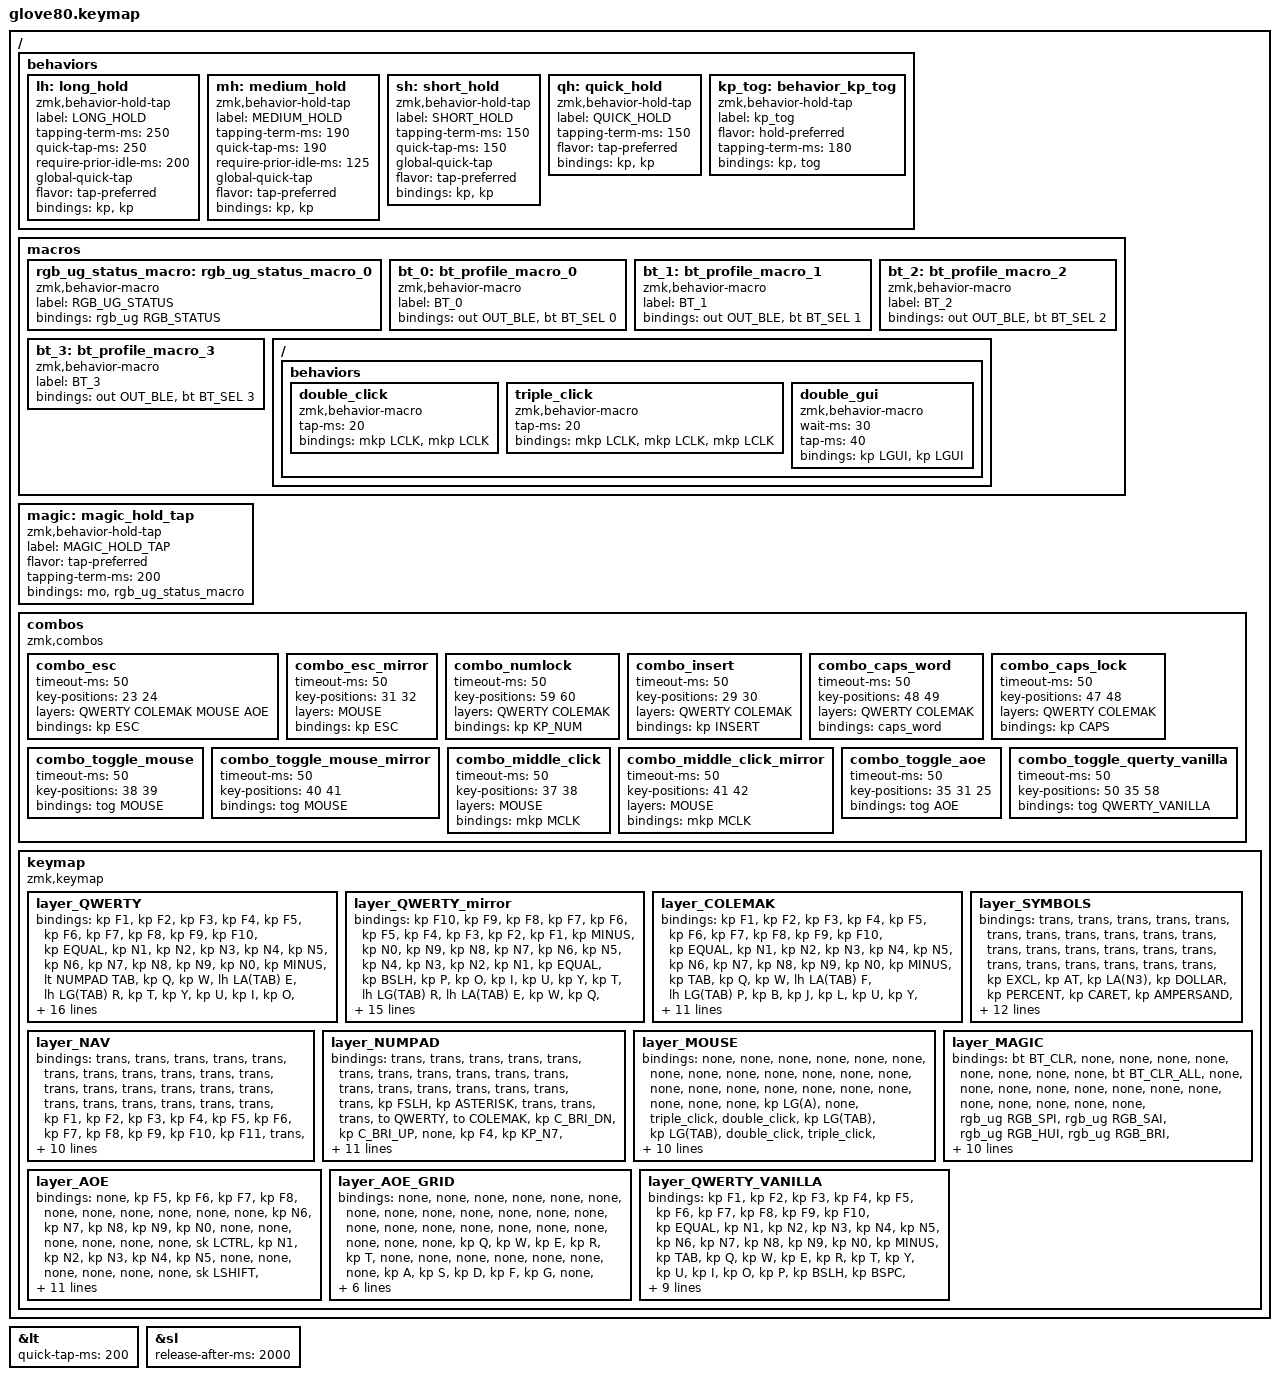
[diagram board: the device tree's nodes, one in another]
/*
 * Copyright (c) 2020 The ZMK Contributors
 * Copyright (c) 2022 Innaworks Development Limited, trading as MoErgo
 *
 * SPDX-License-Identifier: MIT
 */

#include <behaviors.dtsi>
/* Include all behaviour includes needed by system behaviors/macros */
#include <dt-bindings/zmk/outputs.h>

/* Include behaviour includes needed by key binds - automatically generated */
#include <dt-bindings/zmk/keys.h>
#include <dt-bindings/zmk/bt.h>
#include <dt-bindings/zmk/rgb.h>
#include <dt-bindings/zmk/outputs.h>
#include <dt-bindings/zmk/mouse.h>

#define QWERTY 0
#define QWERTY_MIRROR 1
#define COLEMAK 2
#define SYMBOLS 3
#define NAV 4
#define NUMPAD 5
#define MOUSE 6
#define MAGIC 7
#define AOE 8
#define AOE_GRID 9
#define QWERTY_VANILLA 10

#define AS(keycode) &qh LS(keycode) keycode     // Autoshift Macro

&lt {
    quick-tap-ms = <200>;
};

&sl {
    release-after-ms = <2000>;
};

/ {
    behaviors {
        /* Tap and hold with a longer duration for keys that invoke functions (e.g. alt-tabbing, etc.) */
        lh: long_hold {
            compatible = "zmk,behavior-hold-tap";
            label = "LONG_HOLD";
            #binding-cells = <2>;
            tapping-term-ms = <250>;
            quick-tap-ms = <250>;
            require-prior-idle-ms = <200>;
            global-quick-tap;
            flavor = "tap-preferred";
            bindings = <&kp>, <&kp>;
        };

        /* Tap and hold with a medium duration, e.g. for home-row modifiers */
        mh: medium_hold {
            compatible = "zmk,behavior-hold-tap";
            label = "MEDIUM_HOLD";
            #binding-cells = <2>;
            tapping-term-ms = <190>;
            quick-tap-ms = <190>;
            require-prior-idle-ms = <125>;
            global-quick-tap;
            flavor = "tap-preferred";
            bindings = <&kp>, <&kp>;
        };

        /*
           Short holds optimised for faster typing. Use for the shift key home-row mods on character layers.
           Same as medium hold but without require-prior-idle and shorter tapping terms
        */
        sh: short_hold {
            compatible = "zmk,behavior-hold-tap";
            label = "SHORT_HOLD";
            #binding-cells = <2>;
            tapping-term-ms = <150>;
            quick-tap-ms = <150>;
            global-quick-tap;
            flavor = "tap-preferred";
            bindings = <&kp>, <&kp>;
        };

        /* Tap and hold with a short duration for normal keys (i.e. shift left/right keys) */
        qh: quick_hold {
            compatible = "zmk,behavior-hold-tap";
            label = "QUICK_HOLD";
            #binding-cells = <2>;
            tapping-term-ms = <150>;
            flavor = "tap-preferred";
            bindings = <&kp>, <&kp>;
        };

        /* Toggle layer on tap, kp on hold */
        kp_tog: behavior_kp_tog {
            compatible = "zmk,behavior-hold-tap";
            label = "kp_tog";
            #binding-cells = <2>;
            flavor = "hold-preferred";
            tapping-term-ms = <180>;
            bindings = <&kp>, <&tog>;
        };
    };
};

/ {
    macros {
        rgb_ug_status_macro: rgb_ug_status_macro_0 {
            label = "RGB_UG_STATUS";
            compatible = "zmk,behavior-macro";
            #binding-cells = <0>;
            bindings
                = <&rgb_ug RGB_STATUS>;
        };

        bt_0: bt_profile_macro_0 {
            label = "BT_0";
            compatible = "zmk,behavior-macro";
            #binding-cells = <0>;
            bindings
                = <&out OUT_BLE>,
                  <&bt BT_SEL 0>;
        };

        bt_1: bt_profile_macro_1 {
            label = "BT_1";
            compatible = "zmk,behavior-macro";
            #binding-cells = <0>;
            bindings
                = <&out OUT_BLE>,
                  <&bt BT_SEL 1>;
        };

        bt_2: bt_profile_macro_2 {
            label = "BT_2";
            compatible = "zmk,behavior-macro";
            #binding-cells = <0>;
            bindings
                = <&out OUT_BLE>,
                  <&bt BT_SEL 2>;
        };

        bt_3: bt_profile_macro_3 {
            label = "BT_3";
            compatible = "zmk,behavior-macro";
            #binding-cells = <0>;
            bindings
                = <&out OUT_BLE>,
                  <&bt BT_SEL 3>;
        };

        /* Mouse double left-click */
        ZMK_MACRO(double_click,
            tap-ms = <20>;
            bindings = <&mkp LCLK &mkp LCLK>;
        )

        /* Mouse triple left-click */
        ZMK_MACRO(triple_click,
            tap-ms = <20>;
            bindings = <&mkp LCLK &mkp LCLK &mkp LCLK>;
        )

        /* Double press command key (to trigger dictation on mac) */
        ZMK_MACRO(double_gui,
            wait-ms = <30>;
            tap-ms = <40>;
            bindings = <&kp LGUI &kp LGUI>;
        )
    };
};

/ {
    magic: magic_hold_tap {
        compatible = "zmk,behavior-hold-tap";
        label = "MAGIC_HOLD_TAP";
        #binding-cells = <2>;
        flavor = "tap-preferred";
        tapping-term-ms = <200>;
        bindings = <&mo>, <&rgb_ug_status_macro>;
    };
};

    /* Custom Defined Behaviors */
/ {

};

/ {
    combos {
        compatible = "zmk,combos";

        /* ESC when pressing keys in the position of Q & W on the QWERTY keymap simultaneously */
        combo_esc {
            timeout-ms = <50>;
            key-positions = <23 24>;
            layers = <QWERTY COLEMAK MOUSE AOE>;
            bindings = <&kp ESC>;
        };

        /* ESC when pressing keys in the position of O & P on the QWERTY keymap simultaneously */
        combo_esc_mirror {
            timeout-ms = <50>;
            key-positions = <31 32>;
            layers = <MOUSE>;
            bindings = <&kp ESC>;
        };

        /* NUMLOCK when pressing keys in the position of M & comma on the QWERTY keymap simultaneously */
        combo_numlock {
            timeout-ms = <50>;
            key-positions = <59 60>;
            layers = <QWERTY COLEMAK>;
            bindings = <&kp KP_NUM>;
        };

        /* INSERT when pressing keys in the position of U & I on the QWERTY keymap simultaneously */
        combo_insert {
            timeout-ms = <50>;
            key-positions = <29 30>;
            layers = <QWERTY COLEMAK>;
            bindings = <&kp INSERT>;
        };

        /* Caps word when pressing the keys in the position of X & C on the QWERTY keymap simultaneously */
        combo_caps_word {
            timeout-ms = <50>;
            key-positions = <48 49>;
            layers = <QWERTY COLEMAK>;
            bindings = <&caps_word>;
        };

        /* Caps lock when pressing the keys in the position of Z & X on the QWERTY keymap simultaneously */
        combo_caps_lock {
            timeout-ms = <50>;
            key-positions = <47 48>;
            layers = <QWERTY COLEMAK>;
            bindings = <&kp CAPS>;
        };

        /* Toggle the mouse layer when pressing F and G */
        combo_toggle_mouse {
            timeout-ms = <50>;
            key-positions = <38 39>;
            bindings = <&tog MOUSE>;
        };

        /* Toggle the mouse layer when pressing H and J */
        combo_toggle_mouse_mirror {
            timeout-ms = <50>;
            key-positions = <40 41>;
            bindings = <&tog MOUSE>;
        };

        /* Middle mouse click when pressing D & F on the mouse layer */
        combo_middle_click {
            timeout-ms = <50>;
            key-positions = <37 38>;
            layers = <MOUSE>;
            bindings = <&mkp MCLK>;
        };

        /* Middle mouse click when pressing J & K on the mouse layer */
        combo_middle_click_mirror {
            timeout-ms = <50>;
            key-positions = <41 42>;
            layers = <MOUSE>;
            bindings = <&mkp MCLK>;
        };

        /* Toggle the AOE layer when pressing A & O & E */
        combo_toggle_aoe {
            timeout-ms = <50>;
            key-positions = <35 31 25>;
            bindings = <&tog AOE>;
        };

        /* Toggle the QWERTY_VANILLA layer when pressing V & A & N */
        combo_toggle_querty_vanilla {
            timeout-ms = <50>;
            key-positions = <50 35 58>;
            bindings = <&tog QWERTY_VANILLA>;
        };
    };
};

/ {
    keymap {
        compatible = "zmk,keymap";

        layer_QWERTY {
            bindings = <
        &kp F1               &kp F2         &kp F3        &kp F4          &kp F5                                                                                                                                                                                       &kp F6       &kp F7       &kp F8        &kp F9            &kp F10
        &kp EQUAL            &kp N1         &kp N2        &kp N3          &kp N4          &kp N5                                                                                                                                                          &kp N6       &kp N7       &kp N8       &kp N9        &kp N0            &kp MINUS
        &lt NUMPAD TAB       &kp Q          &kp W         &lh LA(TAB) E   &lh LG(TAB) R   &kp T                                                                                                                                                           &kp Y        &kp U        &kp I        &kp O         &kp P             &lt NUMPAD BSLH
        &lt SYMBOLS BSPC     &sh LSHIFT A   &mh LCTRL S   &mh LALT D      &mh LGUI F      &mh LGUI G                                                                                                                                                      &mh RGUI H   &mh RGUI J   &mh LALT K   &mh RCTRL L   &sh RSHIFT SEMI   &lt SYMBOLS RET
        &lt NAV GRAVE        &lh LG(Z) Z    &lh LG(X) X   &mh LG(C) C     &lh LG(V) V     &kp B        &kp_tog LSHFT NAV   &kp_tog LCTRL NUMPAD   &kp_tog LGUI QWERTY_MIRROR        &kp_tog LGUI QWERTY_MIRROR   &kp RCTRL  &kp_tog RSHFT SYMBOLS         &kp N        &kp M        &kp COMMA    &kp DOT       &kp FSLH          &lt NAV PG_UP
        &magic MAGIC QWERTY  &kp HOME       &kp END       &kp LEFT        &kp RIGHT                    &lt NAV BSPC        &lt NUMPAD TAB         &kp LALT                          &kp     RALT                 &kp RET    &lt SYMBOLS SPACE                          &kp UP       &kp DOWN     &kp LBKT      &kp RBKT          &kp PG_DN
            >;
        };

        /* The above layout mirrored */
        layer_QWERTY_mirror {
            bindings = <
        &kp F10     &kp F9            &kp F8        &kp F7        &kp F6                                                                                                                                                                                  &kp F5          &kp F4          &kp F3        &kp F2            &kp F1
        &kp MINUS   &kp N0            &kp N9        &kp N8        &kp N7          &kp N6                                                                                                                                                     &kp N5       &kp N4          &kp N3          &kp N2        &kp N1            &kp EQUAL
        &kp BSLH    &kp P             &kp O         &kp I         &kp U           &kp Y                                                                                                                                                      &kp T        &lh LG(TAB) R   &lh LA(TAB) E   &kp W         &kp Q             &kp TAB
        &kp SQT     &sh RSHIFT SEMI   &mh RCTRL L   &mh LALT K    &mh RGUI J      &mh RGUI H                                                                                                                                                 &mh LGUI G   &mh LGUI F      &mh LALT D      &mh LCTRL S   &sh LSHIFT A      &kp ESC
        &kp PG_UP   &kp FSLH          &kp DOT       &kp COMMA     &kp M           &kp N       &kp_tog RSHFT SYMBOLS   &kp RCTRL   &kp_tog LGUI QWERTY_MIRROR        &kp_tog LGUI QWERTY_MIRROR   &kp_tog LCTRL NUMPAD   &kp_tog LSHFT NAV    &kp B        &lh LG(V) V     &mh LG(C) C     &lh LG(X) X   &lh LG(Z) Z       &kp GRAVE
        &kp PG_DN   &kp RBKT          &kp LBKT      &kp DOWN      &kp UP                      &lt SYMBOLS SPACE       &kp RET     &kp LALT                          &kp     RALT                 &lt NUMPAD TAB         &lt NAV BSPC                      &kp RIGHT       &kp LEFT        &kp END       &kp HOME          &magic MAGIC QWERTY
            >;
        };

        layer_COLEMAK {
            bindings = <
       &kp F1                 &kp F2         &kp F3        &kp F4          &kp F5                                                                                            &kp F6       &kp F7       &kp F8       &kp F9         &kp F10
       &kp EQUAL              &kp N1         &kp N2        &kp N3          &kp N4          &kp N5                                                              &kp N6        &kp N7       &kp N8       &kp N9       &kp N0         &kp MINUS
       &kp TAB                &kp Q          &kp W         &lh LA(TAB) F   &lh LG(TAB) P   &kp B                                                               &kp J         &kp L        &kp U        &kp Y        &kp SEMI       &kp BSLH
       &kp ESC                &sh LSHIFT A   &mh LCTRL R   &mh LALT S      &mh LGUI T      &mh LGUI G                                                          &mh RGUI M    &mh RGUI N   &mh LALT E   &mh RCTRL I  &sh RSHIFT O   &kp SQT
       &kp GRAVE              &lh LG(Z) Z    &lh LG(X) X   &mh LG(C) C     &lh LG(V) D     &kp V       &trans  &trans  &trans       &trans  &trans  &trans     &kp K         &kp H        &kp COMMA    &kp DOT      &kp FSLH       &kp PG_UP
       &magic MAGIC COLEMAK   &kp HOME       &kp END       &kp LEFT        &kp RIGHT                   &trans  &trans  &trans       &trans  &trans  &trans                   &kp UP       &kp DOWN     &kp LBKT     &kp RBKT       &kp PG_DN
            >;
        };

        layer_SYMBOLS {
            bindings = <
        &trans     &trans              &trans          &trans          &trans                                                                                                 &trans          &trans             &trans                  &trans                  &trans
        &trans     &trans              &trans          &trans          &trans                &trans                                                              &trans       &trans          &trans             &trans                  &trans                  &trans
        &trans     &kp EXCL            &kp AT          &kp LA(N3)      &kp DOLLAR            &kp PERCENT                                                         &kp CARET    &kp AMPERSAND   &kp ASTERISK       &kp LEFT_PARENTHESIS    &kp RIGHT_PARENTHESIS   &trans
        &trans     &mh LSHIFT N1       &mh LCTRL N2    &mh LALT N3     &mh LGUI N4           &kp N5                                                              &kp N6       &mh RGUI N7     &mh LALT N8        &mh RCTRL N9            &mh RSHIFT N0           &trans
        &trans     AS(GRAVE)           AS(BACKSLASH)   &none           AS(MINUS)             &none          &trans  &trans  &trans      &trans  &trans  &trans   &kp LS(N3)   AS(EQUAL)       AS(LEFT_BRACKET)   AS(RIGHT_BRACKET)       AS(SINGLE_QUOTE)        &trans
        &trans     &trans              &trans          &trans          &trans                               &trans  &trans  &trans      &trans  &trans  &trans                &trans          &trans             &trans                  &trans                  &trans
            >;
        };

        layer_NAV {
            bindings = <
        &trans    &trans          &trans          &trans        &trans                                                                                            &trans                &trans                &trans               &trans                   &trans
        &trans    &trans          &trans          &trans        &trans           &trans                                                                &trans     &trans                &trans                &trans               &trans                   &trans
        &trans    &kp F1          &kp F2          &kp F3        &kp F4           &kp F5                                                                &kp F6     &kp F7                &kp F8                &kp F9               &kp F10                  &kp F11
        &trans    &mh LSHIFT F11  &mh LCTRL F12   &mh LALT DEL  &mh LGUI ESCAPE  &kp DEL                                                               &none      &kp LEFT_ARROW        &kp DOWN_ARROW        &kp UP_ARROW         &kp RIGHT_ARROW          &kp F12
        &trans    &kp LG(Z)       &kp LG(X)       &kp LG(C)     &kp LG(V)        &kp LG(B)   &trans   &trans  &trans        &trans  &trans  &trans     &kp CAPS   &kp HOME              &kp PG_DN             &kp PG_UP            &kp END                  &trans
        &trans    &trans          &trans          &trans        &trans                       &trans   &trans  &trans        &trans  &trans  &trans                &trans                &trans                &trans               &trans                   &trans
            >;
        };

        layer_NUMPAD {
            bindings = <
        &trans    &trans       &trans        &trans         &trans                                                                                             &trans       &trans        &trans        &trans         &trans
        &trans    &trans       &trans        &trans         &trans         &trans                                                                     &trans   &trans       &kp FSLH      &kp ASTERISK  &trans         &trans
        &trans    &to QWERTY   &to COLEMAK   &kp C_BRI_DN   &kp C_BRI_UP   &none                                                                      &kp F4   &kp KP_N7    &kp KP_N8     &kp KP_N9     &kp KP_MINUS   &trans
        &trans    &none        &none         &kp LG(R)      &kp LG(F)      &none                                                                      &kp F2   &kp KP_N4    &kp KP_N5     &kp KP_N6     &kp KP_PLUS    &trans
        &trans    &kp C_PP     &kp C_NEXT    &kp C_VOL_DN   &kp C_VOL_UP   &kp LS(LG(V))   &trans   &trans   &trans       &trans  &trans  &trans      &none    &kp KP_N1    &kp KP_N2     &kp KP_N3     &kp KP_DOT     &trans
        &trans    &trans       &trans        &trans         &trans                         &trans   &trans   &trans       &trans  &trans  &kp KP_N0            &trans       &trans        &trans        &trans         &trans
            >;
        };

        layer_MOUSE {
            bindings = <
        &none   &none              &none             &none          &none                                                                                                    &none           &none           &none             &none              &none
        &none   &none              &none             &none          &none           &none                                                                      &none         &none           &none           &none             &none              &none
        &none   &kp LG(A)          &none             &triple_click  &double_click   &kp LG(TAB)                                                                &kp LG(TAB)   &double_click   &triple_click   &none             &kp LG(A)          &none
        &none   &sh LSHIFT PG_UP   &sh LCTRL PG_DN   &mkp RCLK      &mkp LCLK       &kp LA(TAB)                                                                &kp LA(TAB)   &mkp LCLK       &mkp RCLK       &sh LCTRL PG_DN   &sh LSHIFT PG_UP   &none
        &none   &kp LG(Z)          &kp LG(X)         &kp LG(C)      &kp LG(V)       &double_gui     &none    &none    &none        &none   &none   &none       &double_gui   &kp LG(V)       &kp LG(C)       &kp LG(X)         &kp LG(Z)          &none
        &none   &none              &none             &none          &none                           &none    &none    &none        &none   &none   &kp KP_N0                 &none           &none           &none             &none              &none
            >;
        };

        layer_MAGIC {
            bindings = <
    &bt BT_CLR            &none            &none            &none            &none                                                                                     &none   &none   &none   &none  &bt BT_CLR_ALL
         &none            &none            &none            &none            &none            &none                                                            &none   &none   &none   &none   &none           &none
         &none  &rgb_ug RGB_SPI  &rgb_ug RGB_SAI  &rgb_ug RGB_HUI  &rgb_ug RGB_BRI  &rgb_ug RGB_TOG                                                            &none   &none   &none   &none   &none           &none
   &bootloader  &rgb_ug RGB_SPD  &rgb_ug RGB_SAD  &rgb_ug RGB_HUD  &rgb_ug RGB_BRD  &rgb_ug RGB_EFF                                                            &none   &none   &none   &none   &none     &bootloader
         &none            &none            &none            &none            &none            &none      &bt_2   &bt_3         &none   &none   &none   &none   &none   &none   &none   &none   &none           &none
         &none            &none            &none            &none            &none                       &bt_0   &bt_1  &out OUT_USB   &none   &none   &none           &none   &none   &none   &none           &to 3
              >;
        };

        layer_AOE {
            bindings = <
        &none        &kp F5                       &kp F6                &kp F7              &kp F8                                                                                                     &none   &none   &none   &none   &none
        &none        &kp N6                       &kp N7                &kp N8              &kp N9              &kp N0                                                                         &none   &none   &none   &none   &none   &none
        &sk LCTRL    &kp N1                       &kp N2                &kp N3              &kp N4              &kp N5                                                                         &none   &none   &none   &none   &none   &none
        &sk LSHIFT   &sh LSHIFT LC(LS(LA(DOT)))   &mh LCTRL LC(A)       &mh LALT SPACE      &kp F5              &mh LC(H) H                                                                    &none   &none   &none   &none   &none   &none
        &kp FSLH     &mh LC(DOT) DOT              &mh LS(LC(C)) COMMA   &kp LC(TAB)         &kp TAB             &kp LC(LS(R))   &kp LBKT       &kp RBKT   &none        &none   &none   &none   &none   &none   &none   &none   &none   &none
        &kp APOS     &mh F1 LS(LC(F1))            &mh F2 LS(LC(F2))     &mh F3 LS(LC(F3))   &mh F4 LS(LC(F4))                   &sl AOE_GRID   &kp Y      &kp BSPC     &none   &none   &none           &none   &none   &none   &none   &none
            >;
        };

        layer_AOE_GRID {
            bindings = <
        &none   &none   &none   &none   &none                                                                             &none   &none   &none   &none   &none
        &none   &none   &none   &none   &none    &none                                                            &none   &none   &none   &none   &none   &none
        &none   &kp Q   &kp W   &kp E   &kp R    &kp T                                                            &none   &none   &none   &none   &none   &none
        &none   &kp A   &kp S   &kp D   &kp F    &kp G                                                            &none   &none   &none   &none   &none   &none
        &none   &kp Z   &kp X   &kp C   &kp V    &kp DEL   &none    &none    &none        &none   &none   &none   &none   &none   &none   &none   &none   &none
        &none   &none   &none   &none   &none              &trans   &none    &none        &none   &none   &none           &none   &none   &none   &none   &none
            >;
        };

        layer_QWERTY_VANILLA {
            bindings = <
        &kp F1               &kp F2         &kp F3        &kp F4          &kp F5                                                                                                                  &kp F6       &kp F7       &kp F8        &kp F9            &kp F10
        &kp EQUAL            &kp N1         &kp N2        &kp N3          &kp N4          &kp N5                                                                                     &kp N6       &kp N7       &kp N8       &kp N9        &kp N0            &kp MINUS
        &kp TAB              &kp Q          &kp W         &kp E           &kp R           &kp T                                                                                      &kp Y        &kp U        &kp I        &kp O         &kp P             &kp BSLH
        &kp BSPC             &kp A          &kp S         &kp D           &kp F           &kp G                                                                                      &kp H        &kp J        &kp K        &kp L         &kp SEMI          &kp SQT
        &kp GRAVE            &kp Z          &kp X         &kp C           &kp V           &kp B      &kp LSHFT   &kp LCTRL    &kp LGUI         &kp RGUI    &kp RCTRL  &kp RSHFT      &kp N        &kp M        &kp COMMA    &kp DOT       &kp FSLH          &kp PG_UP
        &magic MAGIC QWERTY  &kp HOME       &kp END       &kp LEFT        &kp RIGHT                  &kp BSPC    &kp DEL      &kp LALT         &kp RALT    &kp RET    &kp SPACE                   &kp UP       &kp DOWN     &kp LBKT      &kp RBKT          &kp PG_DN
            >;
        };
    };
};
